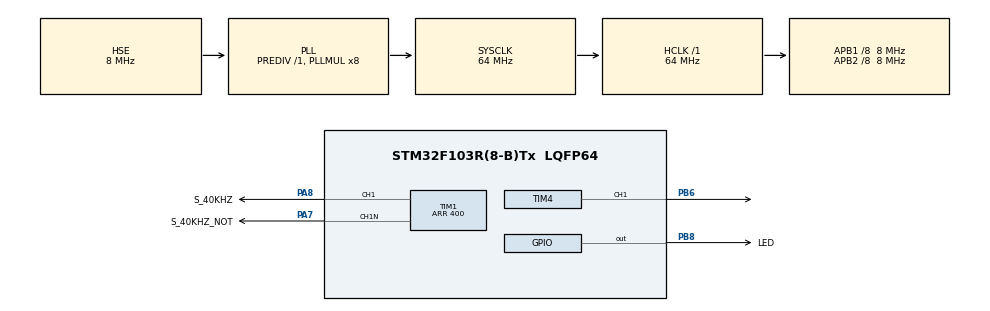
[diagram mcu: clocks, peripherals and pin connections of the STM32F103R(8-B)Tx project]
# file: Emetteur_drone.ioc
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Mcu.Family=STM32F1
Mcu.Name=STM32F103R(8-B)Tx
Mcu.Package=LQFP64
NVIC.PriorityGroup=NVIC_PRIORITYGROUP_4
NVIC.TIM4_IRQn=true\:0\:0\:false
PA7.GPIO_Label=S_40KHZ_NOT
PA7.Mode=PWM Generation1 CH1 CH1N
PA7.Signal=TIM1_CH1N
PA8.GPIO_Label=S_40KHZ
PA8.Signal=S_TIM1_CH1
PB6.Signal=S_TIM4_CH1
PB8.GPIO_Label=LED
PB8.Signal=GPIO_Output
PD0-OSC_IN.Mode=HSE-External-Oscillator
PD0-OSC_IN.Signal=RCC_OSC_IN
PD1-OSC_OUT.Mode=HSE-External-Oscillator
PD1-OSC_OUT.Signal=RCC_OSC_OUT
ProjectManager.TargetToolchain=MDK-ARM V5
RCC.AHBFreq_Value=64000000
RCC.APB1CLKDivider=RCC_HCLK_DIV8
RCC.APB1Freq_Value=8000000
RCC.APB1TimFreq_Value=16000000
RCC.APB2CLKDivider=RCC_HCLK_DIV8
RCC.APB2Freq_Value=8000000
RCC.APB2TimFreq_Value=16000000
RCC.HCLKFreq_Value=64000000
RCC.HSIState=RCC_HSI_ON
RCC.PLLMUL=RCC_PLL_MUL8
RCC.PLLSourceVirtual=RCC_PLLSOURCE_HSE
RCC.SYSCLKFreq_VALUE=64000000
RCC.SYSCLKSource=RCC_SYSCLKSOURCE_PLLCLK
RCC.USBFreq_Value=64000000
SH.S_TIM1_CH1.0=TIM1_CH1,PWM Generation1 CH1 CH1N
SH.S_TIM4_CH1.0=TIM4_CH1,Output Compare1 CH1
TIM1.Period=400
TIM4.Period=1600
TIM4.Prescaler=400
TIM4.Pulse-Output\ Compare1\ CH1=400
TIM4.TIM_MasterOutputTrigger=TIM_TRGO_UPDATE
TIM4.TIM_MasterSlaveMode=TIM_MASTERSLAVEMODE_DISABLE
VP_TIM1_VS_ClockSourceINT.Mode=Internal
board=Emetteur_drone

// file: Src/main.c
/**
  ******************************************************************************
  * File Name          : main.c
  * Description        : Main program body
  ******************************************************************************
  *
  * COPYRIGHT(c) 2016 STMicroelectronics
  *
  * Redistribution and use in source and binary forms, with or without modification,
  * are permitted provided that the following conditions are met:
  *   1. Redistributions of source code must retain the above copyright notice,
  *      this list of conditions and the following disclaimer.
  *   2. Redistributions in binary form must reproduce the above copyright notice,
  *      this list of conditions and the following disclaimer in the documentation
  *      and/or other materials provided with the distribution.
  *   3. Neither the name of STMicroelectronics nor the names of its contributors
  *      may be used to endorse or promote products derived from this software
  *      without specific prior written permission.
  *
  * THIS SOFTWARE IS PROVIDED BY THE COPYRIGHT HOLDERS AND CONTRIBUTORS "AS IS"
  * AND ANY EXPRESS OR IMPLIED WARRANTIES, INCLUDING, BUT NOT LIMITED TO, THE
  * IMPLIED WARRANTIES OF MERCHANTABILITY AND FITNESS FOR A PARTICULAR PURPOSE ARE
  * DISCLAIMED. IN NO EVENT SHALL THE COPYRIGHT HOLDER OR CONTRIBUTORS BE LIABLE
  * FOR ANY DIRECT, INDIRECT, INCIDENTAL, SPECIAL, EXEMPLARY, OR CONSEQUENTIAL
  * DAMAGES (INCLUDING, BUT NOT LIMITED TO, PROCUREMENT OF SUBSTITUTE GOODS OR
  * SERVICES; LOSS OF USE, DATA, OR PROFITS; OR BUSINESS INTERRUPTION) HOWEVER
  * CAUSED AND ON ANY THEORY OF LIABILITY, WHETHER IN CONTRACT, STRICT LIABILITY,
  * OR TORT (INCLUDING NEGLIGENCE OR OTHERWISE) ARISING IN ANY WAY OUT OF THE USE
  * OF THIS SOFTWARE, EVEN IF ADVISED OF THE POSSIBILITY OF SUCH DAMAGE.
  *
  ******************************************************************************
  */
#include "stm32f1xx_hal.h"

TIM_HandleTypeDef htim1;
TIM_HandleTypeDef htim4;

/* USER CODE BEGIN PV */
/* Private variables ---------------------------------------------------------*/

/* USER CODE END PV */

void SystemClock_Config(void);
static void MX_GPIO_Init(void);
static void MX_TIM1_Init(void);
static void MX_TIM4_Init(void);

/* USER CODE BEGIN PFP */
/* Private function prototypes -----------------------------------------------*/

/* USER CODE END PFP */

int main(void)
{

  /* MCU Configuration----------------------------------------------------------*/

  /* Reset of all peripherals, Initializes the Flash interface and the Systick. */
  HAL_Init();

  /* Configure the system clock */
  SystemClock_Config();

  /* Initialize all configured peripherals */
  MX_GPIO_Init();
  MX_TIM1_Init();
  MX_TIM4_Init();

  /* USER CODE BEGIN 2 */
	HAL_TIM_Base_Start(&htim4);
	HAL_TIM_Base_Start_IT(&htim4);
	HAL_TIM_OC_Start(&htim4,TIM_CHANNEL_1);
	HAL_TIM_OC_Start_IT(&htim4,TIM_CHANNEL_1);
	HAL_TIM_PWM_Start(&htim1, TIM_CHANNEL_1);
  /* USER CODE END 2 */

  /* Infinite loop */
  while (1)
  {

  }

}

/** System Clock Configuration
*/
void SystemClock_Config(void)
{

  RCC_OscInitTypeDef RCC_OscInitStruct;
  RCC_ClkInitTypeDef RCC_ClkInitStruct;

  RCC_OscInitStruct.OscillatorType = RCC_OSCILLATORTYPE_HSE;
  RCC_OscInitStruct.HSEState = RCC_HSE_ON;
  RCC_OscInitStruct.HSEPredivValue = RCC_HSE_PREDIV_DIV1;
  RCC_OscInitStruct.PLL.PLLState = RCC_PLL_ON;
  RCC_OscInitStruct.PLL.PLLSource = RCC_PLLSOURCE_HSE;
  RCC_OscInitStruct.PLL.PLLMUL = RCC_PLL_MUL8;
  HAL_RCC_OscConfig(&RCC_OscInitStruct);

  RCC_ClkInitStruct.ClockType = RCC_CLOCKTYPE_SYSCLK|RCC_CLOCKTYPE_PCLK1
                              |RCC_CLOCKTYPE_PCLK2;
  RCC_ClkInitStruct.SYSCLKSource = RCC_SYSCLKSOURCE_PLLCLK;
  RCC_ClkInitStruct.AHBCLKDivider = RCC_SYSCLK_DIV1;
  RCC_ClkInitStruct.APB1CLKDivider = RCC_HCLK_DIV8;
  RCC_ClkInitStruct.APB2CLKDivider = RCC_HCLK_DIV8;
  HAL_RCC_ClockConfig(&RCC_ClkInitStruct, FLASH_LATENCY_2);

  HAL_SYSTICK_Config(HAL_RCC_GetHCLKFreq()/1000);

  HAL_SYSTICK_CLKSourceConfig(SYSTICK_CLKSOURCE_HCLK);

  /* SysTick_IRQn interrupt configuration */
  HAL_NVIC_SetPriority(SysTick_IRQn, 0, 0);
}

/* TIM1 init function */
void MX_TIM1_Init(void)
{

  TIM_ClockConfigTypeDef sClockSourceConfig;
  TIM_MasterConfigTypeDef sMasterConfig;
  TIM_BreakDeadTimeConfigTypeDef sBreakDeadTimeConfig;
  TIM_OC_InitTypeDef sConfigOC;

  htim1.Instance = TIM1;
  htim1.Init.Prescaler = 0;
  htim1.Init.CounterMode = TIM_COUNTERMODE_UP;
  htim1.Init.Period = 400;
  htim1.Init.ClockDivision = TIM_CLOCKDIVISION_DIV1;
  htim1.Init.RepetitionCounter = 0;
  HAL_TIM_Base_Init(&htim1);

  sClockSourceConfig.ClockSource = TIM_CLOCKSOURCE_INTERNAL;
  HAL_TIM_ConfigClockSource(&htim1, &sClockSourceConfig);

  HAL_TIM_PWM_Init(&htim1);

  sMasterConfig.MasterOutputTrigger = TIM_TRGO_RESET;
  sMasterConfig.MasterSlaveMode = TIM_MASTERSLAVEMODE_DISABLE;
  HAL_TIMEx_MasterConfigSynchronization(&htim1, &sMasterConfig);

  sBreakDeadTimeConfig.OffStateRunMode = TIM_OSSR_DISABLE;
  sBreakDeadTimeConfig.OffStateIDLEMode = TIM_OSSI_DISABLE;
  sBreakDeadTimeConfig.LockLevel = TIM_LOCKLEVEL_OFF;
  sBreakDeadTimeConfig.DeadTime = 0;
  sBreakDeadTimeConfig.BreakState = TIM_BREAK_DISABLE;
  sBreakDeadTimeConfig.BreakPolarity = TIM_BREAKPOLARITY_HIGH;
  sBreakDeadTimeConfig.AutomaticOutput = TIM_AUTOMATICOUTPUT_DISABLE;
  HAL_TIMEx_ConfigBreakDeadTime(&htim1, &sBreakDeadTimeConfig);

  sConfigOC.OCMode = TIM_OCMODE_PWM1;
  sConfigOC.Pulse = 0;
  sConfigOC.OCPolarity = TIM_OCPOLARITY_HIGH;
  sConfigOC.OCNPolarity = TIM_OCNPOLARITY_HIGH;
  sConfigOC.OCFastMode = TIM_OCFAST_DISABLE;
  sConfigOC.OCIdleState = TIM_OCIDLESTATE_RESET;
  sConfigOC.OCNIdleState = TIM_OCNIDLESTATE_RESET;
  HAL_TIM_PWM_ConfigChannel(&htim1, &sConfigOC, TIM_CHANNEL_1);

}

/* TIM4 init function */
void MX_TIM4_Init(void)
{

  TIM_MasterConfigTypeDef sMasterConfig;
  TIM_OC_InitTypeDef sConfigOC;

  htim4.Instance = TIM4;
  htim4.Init.Prescaler = 400;
  htim4.Init.CounterMode = TIM_COUNTERMODE_UP;
  htim4.Init.Period = 1600;
  htim4.Init.ClockDivision = TIM_CLOCKDIVISION_DIV1;
  HAL_TIM_OC_Init(&htim4);

  sMasterConfig.MasterOutputTrigger = TIM_TRGO_UPDATE;
  sMasterConfig.MasterSlaveMode = TIM_MASTERSLAVEMODE_DISABLE;
  HAL_TIMEx_MasterConfigSynchronization(&htim4, &sMasterConfig);

  sConfigOC.OCMode = TIM_OCMODE_TIMING;
  sConfigOC.Pulse = 400;
  sConfigOC.OCPolarity = TIM_OCPOLARITY_HIGH;
  sConfigOC.OCFastMode = TIM_OCFAST_DISABLE;
  HAL_TIM_OC_ConfigChannel(&htim4, &sConfigOC, TIM_CHANNEL_1);

}

/** Configure pins as
        * Analog
        * Input
        * Output
        * EVENT_OUT
        * EXTI
*/
void MX_GPIO_Init(void)
{

  GPIO_InitTypeDef GPIO_InitStruct;

  /* GPIO Ports Clock Enable */
  __GPIOD_CLK_ENABLE();
  __GPIOA_CLK_ENABLE();
  __GPIOB_CLK_ENABLE();

  /*Configure GPIO pin : LED_Pin */
  GPIO_InitStruct.Pin = LED_Pin;
  GPIO_InitStruct.Mode = GPIO_MODE_OUTPUT_PP;
  GPIO_InitStruct.Speed = GPIO_SPEED_LOW;
  HAL_GPIO_Init(LED_GPIO_Port, &GPIO_InitStruct);

}

/************************ (C) COPYRIGHT STMicroelectronics *****END OF FILE****/
